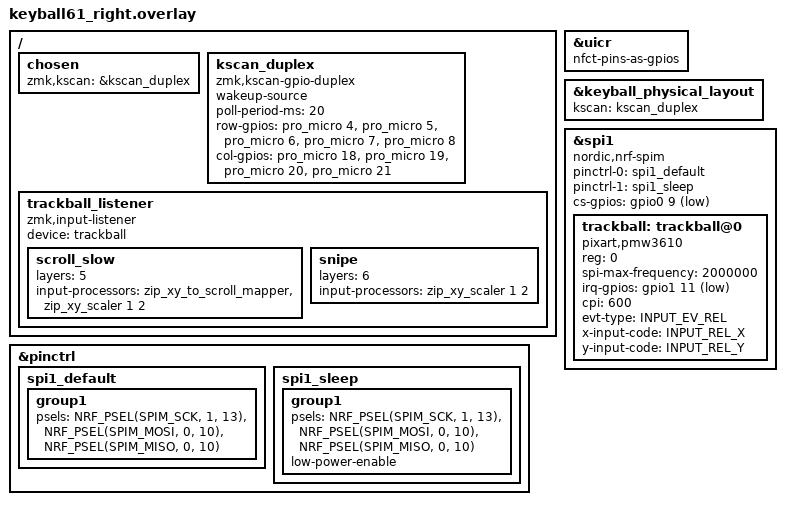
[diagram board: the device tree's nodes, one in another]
#include <behaviors.dtsi>
#include "keyball61.dtsi"

&uicr {
    nfct-pins-as-gpios;
};

/ {
    chosen {
        zmk,kscan = &kscan_duplex;
    };

    kscan_duplex: kscan_duplex {
        compatible = "zmk,kscan-gpio-duplex";
        wakeup-source;
        poll-period-ms = <20>;
        row-gpios
            = <&pro_micro 4 GPIO_ACTIVE_HIGH>
            , <&pro_micro 5 GPIO_ACTIVE_HIGH>
            , <&pro_micro 6 GPIO_ACTIVE_HIGH>
            , <&pro_micro 7 GPIO_ACTIVE_HIGH>
            , <&pro_micro 8 GPIO_ACTIVE_HIGH>
            ;

        col-gpios
            = <&pro_micro 18 GPIO_ACTIVE_HIGH>
            , <&pro_micro 19 GPIO_ACTIVE_HIGH>
            , <&pro_micro 20 GPIO_ACTIVE_HIGH>
            , <&pro_micro 21 GPIO_ACTIVE_HIGH>
            ;
    };
};

&keyball_physical_layout {
    kscan = <&kscan_duplex>;
};

&pinctrl {
    spi1_default: spi1_default {
        group1 {
            psels = <NRF_PSEL(SPIM_SCK, 1, 13)>,
                    <NRF_PSEL(SPIM_MOSI, 0, 10)>,
                    <NRF_PSEL(SPIM_MISO, 0, 10)>;
        };
    };

    spi1_sleep: spi1_sleep {
        group1 {
            psels = <NRF_PSEL(SPIM_SCK, 1, 13)>,
                    <NRF_PSEL(SPIM_MOSI, 0, 10)>,
                    <NRF_PSEL(SPIM_MISO, 0, 10)>;
            low-power-enable;
        };
    };
};

&spi1 {
    status = "okay";
    compatible = "nordic,nrf-spim";
    pinctrl-0 = <&spi1_default>;
    pinctrl-1 = <&spi1_sleep>;
    pinctrl-names = "default", "sleep";
    cs-gpios = <&gpio0 9 GPIO_ACTIVE_LOW>;

    trackball: trackball@0 {
        status = "okay";
        compatible = "pixart,pmw3610";
        reg = <0>;
        spi-max-frequency = <2000000>;
        irq-gpios = <&gpio1 11 (GPIO_ACTIVE_LOW | GPIO_PULL_UP)>;
        cpi = <600>;
        evt-type = <INPUT_EV_REL>;
        x-input-code = <INPUT_REL_X>;
        y-input-code = <INPUT_REL_Y>;
    };
};

/ {
    trackball_listener {
        compatible = "zmk,input-listener";
        device = <&trackball>;

        scroll_slow {
            layers = <5>;
            input-processors = <&zip_xy_to_scroll_mapper>, <&zip_xy_scaler 1 2>;
        };

        snipe {
            layers = <6>;
            input-processors = <&zip_xy_scaler 1 2>;
        };
    };
};
